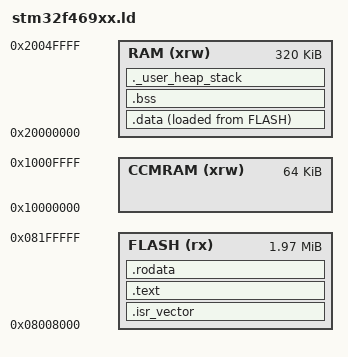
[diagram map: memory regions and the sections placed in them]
/*
 * Linker Script for STM32F469NI - Application
 * Application starts at 0x08008000 (Sector 2).
 * Length is reduced by 32KB (Sector 0+1) to accommodate Bootloader/Config.
 */

ENTRY(Reset_Handler)

_estack = 0x20050000;    /* end of RAM (320KB) */

MEMORY
{
  FLASH (rx)      : ORIGIN = 0x08008000, LENGTH = 2048K - 32K
  RAM (xrw)       : ORIGIN = 0x20000000, LENGTH = 320K
  CCMRAM (xrw)    : ORIGIN = 0x10000000, LENGTH = 64K
}

SECTIONS
{
  .isr_vector :
  {
    . = ALIGN(4);
    KEEP(*(.isr_vector))
    . = ALIGN(4);
  } >FLASH

  .text :
  {
    . = ALIGN(4);
    *(.text)           /* .text sections (code) */
    *(.text*)          /* .text* sections (code) */
    *(.glue_7)         /* glue arm to thumb code */
    *(.glue_7t)        /* glue thumb to arm code */
    *(.eh_frame)

    KEEP (*(.init))
    KEEP (*(.fini))

    . = ALIGN(4);
    _etext = .;        /* define a global symbols at end of code */
  } >FLASH

  .rodata :
  {
    . = ALIGN(4);
    *(.rodata)         /* .rodata sections (constants, strings, etc.) */
    *(.rodata*)        /* .rodata* sections (constants, strings, etc.) */
    . = ALIGN(4);
  } >FLASH

  .data :
  {
    . = ALIGN(4);
    _sdata = .;        /* create a global symbol at data start */
    *(.data)           /* .data sections */
    *(.data*)          /* .data* sections */
    . = ALIGN(4);
    _edata = .;        /* define a global symbol at data end */
  } >RAM AT> FLASH

  _sidata = LOADADDR(.data);

  .bss :
  {
    . = ALIGN(4);
    _sbss = .;         /* define a global symbol at bss start */
    __bss_start__ = _sbss;
    *(.bss)
    *(.bss*)
    *(COMMON)

    . = ALIGN(4);
    _ebss = .;         /* define a global symbol at bss end */
    __bss_end__ = _ebss;
  } >RAM

  ._user_heap_stack :
  {
    . = ALIGN(8);
    PROVIDE ( end = . );
    PROVIDE ( _end = . );
    . = . + 0x400; /* Min_Heap_Size */
    . = . + 0x800; /* Min_Stack_Size */
    . = ALIGN(8);
  } >RAM
}
